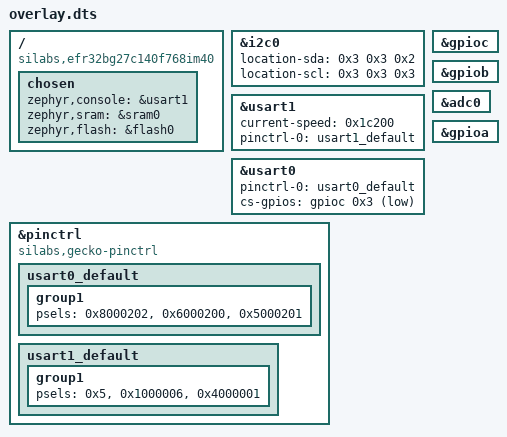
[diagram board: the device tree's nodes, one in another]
/ {
	compatible = "silabs,efr32bg27c140f768im40", "silabs,efr32bg27_brd2602a", "silabs,efr32bg27";
	chosen {
		zephyr,console = &usart1;
		zephyr,sram = &sram0;
		zephyr,flash = &flash0;
	};
};
&i2c0{
	status = "okay";
	location-sda = < 0x3 0x3 0x2 >;
	location-scl = < 0x3 0x3 0x3 >;
};
&usart1{
	status = "okay";
	current-speed = < 0x1c200 >;
	pinctrl-0 = < &usart1_default >;
	pinctrl-names = "default";
};
&usart0{
	status = "okay";
	pinctrl-0 = < &usart0_default >;
	pinctrl-names = "default";
	cs-gpios = < &gpioc 0x3 0x1 >;
};
&gpioc{
	status = "okay";
};
&gpiob{
	status = "okay";
};
&adc0{
	status = "okay";
};
&gpioa{
	status = "okay";
};
&pinctrl{
	compatible = "silabs,gecko-pinctrl";
	usart0_default: usart0_default {
		group1 {
			psels = < 0x8000202 >, < 0x6000200 >, < 0x5000201 >;
		};
	};
	usart1_default: usart1_default {
		group1 {
			psels = < 0x5 >, < 0x1000006 >, < 0x4000001 >;
		};
	};
};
